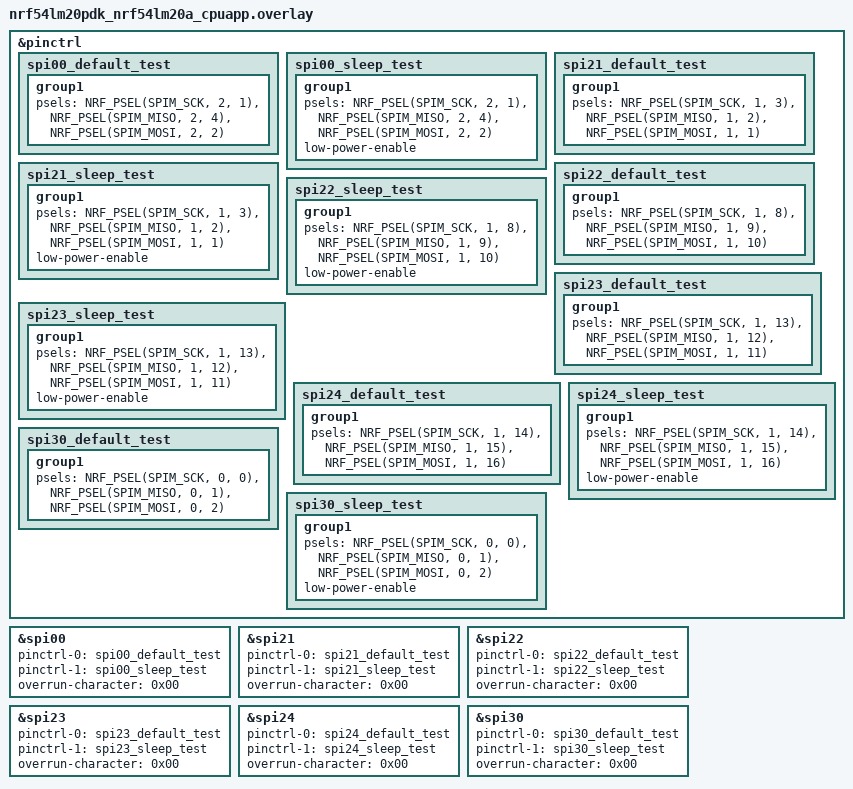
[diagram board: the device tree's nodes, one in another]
/*
 * Copyright (c) 2025 Nordic Semiconductor ASA
 *
 * SPDX-License-Identifier: LicenseRef-Nordic-5-Clause
 */

&pinctrl {
	spi00_default_test: spi00_default_test {
		group1 {
			psels = <NRF_PSEL(SPIM_SCK, 2, 1)>,
				<NRF_PSEL(SPIM_MISO, 2, 4)>,
				<NRF_PSEL(SPIM_MOSI, 2, 2)>;
		};
	};

	spi00_sleep_test: spi00_sleep_test {
		group1 {
			psels = <NRF_PSEL(SPIM_SCK, 2, 1)>,
				<NRF_PSEL(SPIM_MISO, 2, 4)>,
				<NRF_PSEL(SPIM_MOSI, 2, 2)>;
			low-power-enable;
		};
	};

	spi21_default_test: spi21_default_test {
		group1 {
			psels = <NRF_PSEL(SPIM_SCK, 1, 3)>,
				<NRF_PSEL(SPIM_MISO, 1, 2)>,
				<NRF_PSEL(SPIM_MOSI, 1, 1)>;
		};
	};

	spi21_sleep_test: spi21_sleep_test {
		group1 {
			psels = <NRF_PSEL(SPIM_SCK, 1, 3)>,
				<NRF_PSEL(SPIM_MISO, 1, 2)>,
				<NRF_PSEL(SPIM_MOSI, 1, 1)>;
			low-power-enable;
		};
	};

	spi22_default_test: spi22_default_test {
		group1 {
			psels = <NRF_PSEL(SPIM_SCK, 1, 8)>,
				<NRF_PSEL(SPIM_MISO, 1, 9)>,
				<NRF_PSEL(SPIM_MOSI, 1, 10)>;
		};
	};

	spi22_sleep_test: spi22_sleep_test {
		group1 {
			psels = <NRF_PSEL(SPIM_SCK, 1, 8)>,
				<NRF_PSEL(SPIM_MISO, 1, 9)>,
				<NRF_PSEL(SPIM_MOSI, 1, 10)>;
			low-power-enable;
		};
	};

	spi23_default_test: spi23_default_test {
		group1 {
			psels = <NRF_PSEL(SPIM_SCK, 1, 13)>,
				<NRF_PSEL(SPIM_MISO, 1, 12)>,
				<NRF_PSEL(SPIM_MOSI, 1, 11)>;
		};
	};

	spi23_sleep_test: spi23_sleep_test {
		group1 {
			psels = <NRF_PSEL(SPIM_SCK, 1, 13)>,
				<NRF_PSEL(SPIM_MISO, 1, 12)>,
				<NRF_PSEL(SPIM_MOSI, 1, 11)>;
			low-power-enable;
		};
	};

	spi24_default_test: spi24_default_test {
		group1 {
			psels = <NRF_PSEL(SPIM_SCK, 1, 14)>,
				<NRF_PSEL(SPIM_MISO, 1, 15)>,
				<NRF_PSEL(SPIM_MOSI, 1, 16)>;
		};
	};

	spi24_sleep_test: spi24_sleep_test {
		group1 {
			psels = <NRF_PSEL(SPIM_SCK, 1, 14)>,
				<NRF_PSEL(SPIM_MISO, 1, 15)>,
				<NRF_PSEL(SPIM_MOSI, 1, 16)>;
			low-power-enable;
		};
	};

	spi30_default_test: spi30_default_test {
		group1 {
			psels = <NRF_PSEL(SPIM_SCK, 0, 0)>,
				<NRF_PSEL(SPIM_MISO, 0, 1)>,
				<NRF_PSEL(SPIM_MOSI, 0, 2)>;
		};
	};

	spi30_sleep_test: spi30_sleep_test {
		group1 {
			psels = <NRF_PSEL(SPIM_SCK, 0, 0)>,
				<NRF_PSEL(SPIM_MISO, 0, 1)>,
				<NRF_PSEL(SPIM_MOSI, 0, 2)>;
			low-power-enable;
		};
	};
};

/delete-node/ &mx25r64;

&spi00 {
	status = "okay";
	pinctrl-0 = <&spi00_default_test>;
	pinctrl-1 = <&spi00_sleep_test>;
	pinctrl-names = "default", "sleep";
	overrun-character = <0x00>;
};

/* spi20 inaccessible due to console on uart20 */

&spi21 {
	status = "okay";
	pinctrl-0 = <&spi21_default_test>;
	pinctrl-1 = <&spi21_sleep_test>;
	pinctrl-names = "default", "sleep";
	overrun-character = <0x00>;
};

&spi22 {
	status = "okay";
	pinctrl-0 = <&spi22_default_test>;
	pinctrl-1 = <&spi22_sleep_test>;
	pinctrl-names = "default", "sleep";
	overrun-character = <0x00>;
};

&spi23 {
	status = "okay";
	pinctrl-0 = <&spi23_default_test>;
	pinctrl-1 = <&spi23_sleep_test>;
	pinctrl-names = "default", "sleep";
	overrun-character = <0x00>;
};

&spi24 {
	status = "okay";
	pinctrl-0 = <&spi24_default_test>;
	pinctrl-1 = <&spi24_sleep_test>;
	pinctrl-names = "default", "sleep";
	overrun-character = <0x00>;
};

&spi30 {
	status = "okay";
	pinctrl-0 = <&spi30_default_test>;
	pinctrl-1 = <&spi30_sleep_test>;
	pinctrl-names = "default", "sleep";
	overrun-character = <0x00>;
};
